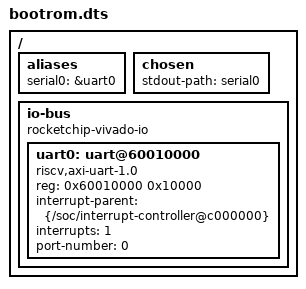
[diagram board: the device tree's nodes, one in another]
/ {

    aliases {
        serial0 = &uart0;
    };

    chosen {
        stdout-path = "serial0";
    };

    io-bus {
        #address-cells = <1>;
        #size-cells = <1>;
        compatible = "rocketchip-vivado-io", "simple-bus";
        ranges;

        uart0: uart@60010000 {
            compatible = "riscv,axi-uart-1.0";
            reg = <0x60010000 0x10000>;
            interrupt-parent = <&{/soc/interrupt-controller@c000000}>;
            interrupts = <1>;
            port-number = <0>;
        };
    };
};
